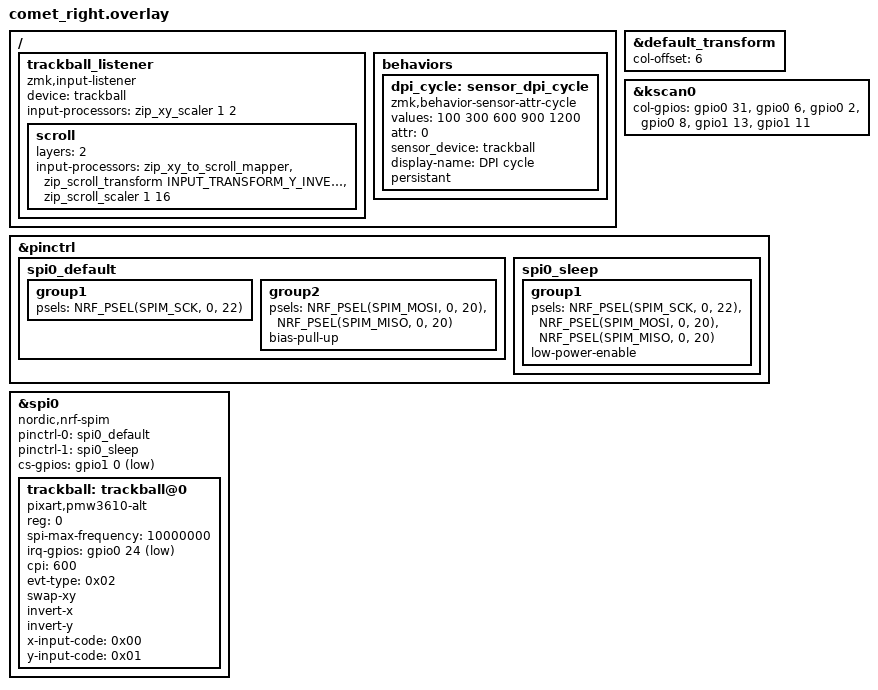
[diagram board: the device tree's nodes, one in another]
/*
 * Copyright (c) 2026 The ZMK Contributors
 *
 * SPDX-License-Identifier: MIT
 */

#include "comet.dtsi"
#include <input/processors.dtsi>
#include <dt-bindings/zmk/input_transform.h>

/ {
  trackball_listener {
    compatible = "zmk,input-listener";
    device = <&trackball>;

    /*
     * Scale mouse movement to 1/2 of raw sensor output.
     * This slows and smooths the cursor without changing CPI (which causes
     * jitter on the PMW3610). Adjust the ratio (numerator denominator) to
     * taste: 1 2 = 50%, 3 4 = 75%, 1 3 = 33%.
     */
    input-processors = <&zip_xy_scaler 1 2>;

    scroll {
        layers = <2>;
        /*
         * Chain: map XY to scroll, invert vertical (Y) scroll only, then scale.
         * zip_scroll_transform fixes scroll direction without affecting mouse.
         */
        input-processors = <&zip_xy_to_scroll_mapper &zip_scroll_transform INPUT_TRANSFORM_Y_INVERT &zip_scroll_scaler 1 16>;
    };
  };

  behaviors {
        dpi_cycle: sensor_dpi_cycle {
            compatible = "zmk,behavior-sensor-attr-cycle";
            #binding-cells = <1>;
            /* PMW3610 supports multiples of 200 CPI. Valid range: 200-3200. */
            values = <400 800 1200 1600 2400>;
            attr = <0>;
            sensor_device = <&trackball>;
            display-name = "DPI cycle";
            persistant;
        };
    };
};

&default_transform {
    col-offset = <6>;
};

&kscan0 {
    col-gpios
        = <&gpio0 31 GPIO_ACTIVE_HIGH>  // P0.31 (A0/D14) - outer
        , <&gpio0 6  GPIO_ACTIVE_HIGH>  // P0.29 (A1/D15) - pinky
        , <&gpio0 2 GPIO_ACTIVE_HIGH>   // P0.02 (A2/D16) - ring
        , <&gpio0 8 GPIO_ACTIVE_HIGH>  // P1.15 (A3/D17) - middle
        , <&gpio1 13 GPIO_ACTIVE_HIGH>  // P1.13 (D18) - index
        , <&gpio1 11 GPIO_ACTIVE_HIGH>  // P1.10 (D19) - inner
        ;
};

&pinctrl {
    spi0_default: spi0_default {
        group1 {
            psels = <NRF_PSEL(SPIM_SCK, 0, 22)>;
        };
        group2 {
            psels = <NRF_PSEL(SPIM_MOSI, 0, 20)>,
                <NRF_PSEL(SPIM_MISO, 0, 20)>;
            bias-pull-up;
        };
    };

    spi0_sleep: spi0_sleep {
        group1 {
            psels = <NRF_PSEL(SPIM_SCK, 0, 22)>,
                <NRF_PSEL(SPIM_MOSI, 0, 20)>,
                <NRF_PSEL(SPIM_MISO, 0, 20)>;
            low-power-enable;
        };
    };
};

&spi0 {
    status = "okay";
    compatible = "nordic,nrf-spim";
    pinctrl-0 = <&spi0_default>;
    pinctrl-1 = <&spi0_sleep>;
    pinctrl-names = "default", "sleep";
    cs-gpios = <&gpio1 0 GPIO_ACTIVE_LOW>;

    trackball: trackball@0 {
        status = "okay";
        compatible = "pixart,pmw3610-alt";
        reg = <0>;
        spi-max-frequency = <10000000>;
        irq-gpios = <&gpio0 24 (GPIO_ACTIVE_LOW | GPIO_PULL_UP)>;
        cpi = <600>;
        evt-type = <0x02>;
        swap-xy;
        invert-x;
        invert-y;
        x-input-code = <0x00>;
        y-input-code = <0x01>;

        /*
         * DO NOT use force-awake: it keeps the sensor always active, causing
         * spurious motion reports from noise/vibration when idle. This leads
         * to the cursor randomly snapping to corners. Let the sensor sleep
         * when idle instead.
         */
        /* force-awake; */
        /* force-awake-4ms-mode; */

        /*   optional: ball action on specific layers  */
        // arrows {
        //     layers = <3>;
        //     bindings =
        //         <&kp RIGHT_ARROW>,
        //         <&kp LEFT_ARROW>,
        //         <&kp UP_ARROW>,
        //         <&kp DOWN_ARROW>;
        //
        //     /*   optional: ball action configuration  */
        //     tick = <10>;
        //     // wait-ms = <5>;
        //     // tap-ms = <5>;
        // };
    };
};

/ {
    behaviors {
        dpi_cycle: sensor_dpi_cycle {
            compatible = "zmk,behavior-sensor-attr-cycle";
            #binding-cells = <1>;
            values = < 100 300 600 900 1200 >;
            attr = <0>;
            sensor_device = <&trackball>;
            display-name = "DPI cycle";
            persistant;
        };
    };
};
